# AE402FA0E5597BE0_CM55_HE_View register map
Vendor: Alif Semiconductor; Series: E4; File version: 1.0
CPU: CM55 r1p0, selectable endian, MPU, FPU, double-precision FPU, DSP, VTOR, 8 interrupt priority bits, 1 SAU regions
Registers are 32-bit, read-write, reset 0x0 unless marked. A register's access mark holds for its fields unless they carry their own. Offsets are from the block's base; [hi:lo] are bit positions.

## ETH (part 4 of 4)
Base 0x48100000
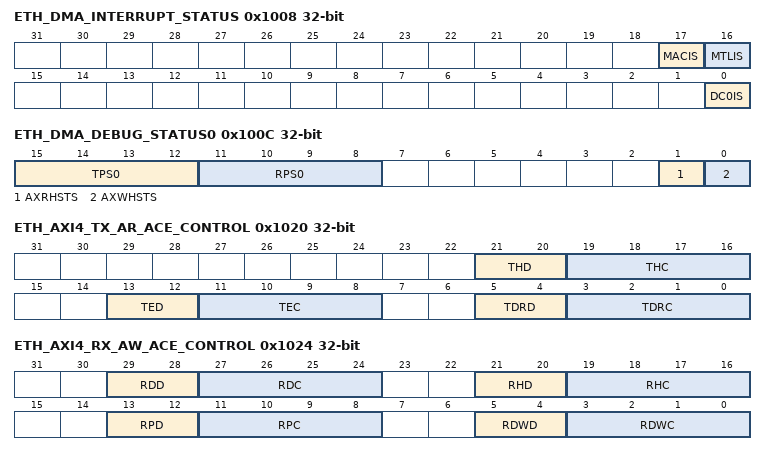
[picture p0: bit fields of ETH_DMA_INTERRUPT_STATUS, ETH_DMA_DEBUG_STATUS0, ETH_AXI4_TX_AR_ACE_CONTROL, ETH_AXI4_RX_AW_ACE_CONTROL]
0x1008 ETH_DMA_INTERRUPT_STATUS ro — DMA, MTL, and MAC Interrupt Status Register
  [17] MACIS — MAC Interrupt Status This bit indicates an interrupt event in the MAC. To reset this bit to 0x0, the software must read the corresponding register in the MAC to get the exact cause of the interrupt and clear its source.
    0=MAC interrupt status not detected; 1=MAC interrupt status detected
  [16] MTLIS — MTL Interrupt Status This bit indicates an interrupt event in the MTL. To reset this bit to 0x0, the software must read the corresponding register in the MTL to get the exact cause of the interrupt and clear its source.
    0=MTL interrupt status not detected; 1=MTL interrupt status detected
  [0] DC0IS — DMA Channel 0 Interrupt Status This bit indicates an interrupt event in DMA Channel 0. To reset this bit to 0x0, the software must read the corresponding register in DMA Channel 0 to get the exact cause of the interrupt and clear its source.
    0=DMA channel 0 interrupt status not detected; 1=DMA channel 0 interrupt status detected
0x100C ETH_DMA_DEBUG_STATUS0 ro — Debug Status 0 Register
  [15:12] TPS0 — DMA Channel 0 Transmit Process State This field indicates the Tx DMA FSM state for Channel 0. The MSB of this field always returns 0. This field does not generate an interrupt.
    0=Stopped (reset or stop transmit command issued); 1=Running (fetching Tx transfer descriptor); 2=Running (waiting for status); 3=Running (reading data from system memory buffer and queuing it to the Tx buffer (Tx FIFO)); 4=Timestamp write state; 6=Suspended (Tx descriptor unavailable or Tx buffer underflow); 7=Running (closing Tx descriptor)
  [11:8] RPS0 — DMA Channel 0 Receive Process State This field indicates the Rx DMA FSM state for Channel 0. The MSB of this field always returns 0. This field does not generate an interrupt.
    0=Stopped (reset or stop receive command issued); 1=Running (fetching Rx transfer descriptor); 3=Running (waiting for Rx packet); 4=Suspended (Rx descriptor unavailable); 5=Running (closing the Rx descriptor); 6=Timestamp write state; 7=Running (transferring the received packet data from the Rx buffer to the system memory)
  [1] AXRHSTS — AXI Master Read Channel Status When high, this bit indicates that the read channel of the AXI master is active, and it is transferring the data.
    0=AXI master read channel status not detected; 1=AXI master read channel status detected
  [0] AXWHSTS — AXI Master Write Channel When high, this bit indicates that the write channel of the AXI master is active, and it is transferring data.
    0=AXI master write channel status not detected; 1=AXI master write channel status detected
0x1020 ETH_AXI4_TX_AR_ACE_CONTROL — AXI4 TX DMA Read ACE Control Register
  [21:20] THD — Transmit DMA First Packet Buffer or TSO Header Domain Control When TSO is NOT enabled, This field is used to drive ardomain_m_o[1:0] signal when Transmit DMA is accessing First Buffer of the Packet (First valid buffer with FD being set in the TDES3 of the Descriptor).When TSO is enabled, This field is used to drive ardomain_m_o[1:0] signal when the Transmit DMA is accessing the TSO Header data.
  [19:16] THC — Transmit DMA First Packet Buffer or TSO Header Cache Control When TSO is NOT enabled, This field is used to drive arcache_m_o[3:0] signal when Transmit DMA is accessing First Buffer of the Packet (First valid buffer with FD being set in the TDES3 of the Descriptor).When TSO is enabled, This field is used to drive arcache_m_o[3:0] signal when the Transmit DMA is accessing the TSO Header data.
  [13:12] TED — Transmit DMA Extended Packet Buffer or TSO Payload Domain Control When TSO is NOT enabled, This field is used to drive ardomain_m_o[1:0] signal when Transmit DMA is accessing the extended buffers (when packet is distributed across multiple buffers).When TSO is enabled, This field is used to drive ardomain_m_o[1:0] signal when the Transmit DMA is accessing the TSO payload data.
  [11:8] TEC — Transmit DMA Extended Packet Buffer or TSO Payload Cache Control When TSO is NOT enabled, This field is used to drive arcache_m_o[3:0] signal when Transmit DMA is accessing the extended buffers (when packet is distributed across multiple buffers).When TSO is enabled, This field is used to drive arcache_m_o[3:0] signal when the Transmit DMA is accessing the TSO payload data.
  [5:4] TDRD — Transmit DMA Read Descriptor Domain Control This field is used to drive ardomain_m_o[1:0] signal when Transmit DMA engines access the Descriptor.
  [3:0] TDRC — Transmit DMA Read Descriptor Cache Control This field is used to drive arcache_m_o[3:0] signal when Transmit DMA engines access the Descriptor.
0x1024 ETH_AXI4_RX_AW_ACE_CONTROL — AXI4 RX DMA Write ACE Control Register
  [29:28] RDD — Receive DMA Buffer Domain Control This field is used to drive the awdomain_m_o[1:0] signal when Receive DMA is accessing the Buffer when Header and payload are NOT separated.
  [27:24] RDC — Receive DMA Buffer Cache Control This field is used to drive awcache_m_o[3:0] signal when Receive DMA is accessing the Buffer when Header and payload are NOT separated.
  [21:20] RHD — Receive DMA Header Domain Control This field is used to drive awdomain_m_o[1:0] and signal when Receive DMA is accessing the header Buffer when Header and payload are separated.
  [19:16] RHC — Receive DMA Header Cache Control This field is used to drive awcache_m_o[3:0] and signal when Receive DMA is accessing the header Buffer when Header and payload are separated.
  [13:12] RPD — Receive DMA Payload Domain Control This field is used to drive awdomain_m_o[1:0] signal when Receive DMA is accessing the Payload Buffer when Header and payload are separated.
  [11:8] RPC — Receive DMA Payload Cache Control This field is used to drive awcache_m_o[3:0] signal when Receive DMA is accessing the Payload Buffer when Header and payload are separated.
  [5:4] RDWD — Receive DMA Write Descriptor Domain Control This field is used to drive awdomain_m_o[1:0] signal when Receive DMA accesses the Descriptor.
  [3:0] RDWC — Receive DMA Write Descriptor Cache Control This field is used to drive awcache_m_o[3:0] signal when Receive DMA accesses the Descriptor.
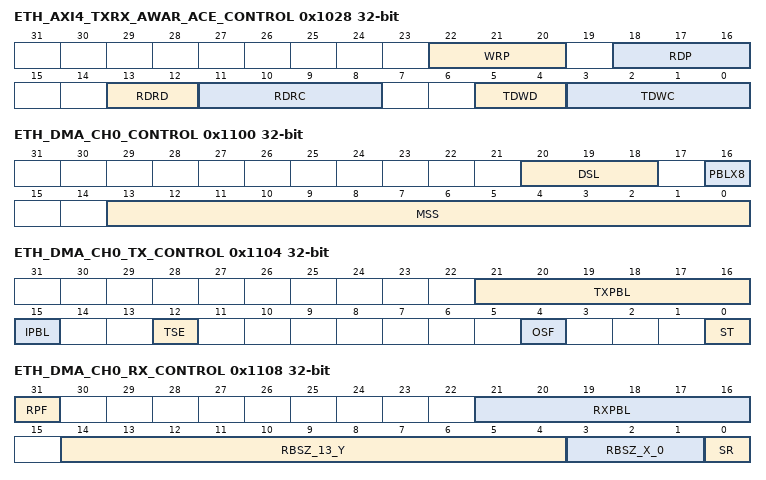
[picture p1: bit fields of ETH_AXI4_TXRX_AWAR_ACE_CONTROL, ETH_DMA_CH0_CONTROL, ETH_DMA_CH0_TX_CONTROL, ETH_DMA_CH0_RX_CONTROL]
0x1028 ETH_AXI4_TXRX_AWAR_ACE_CONTROL — AXI4 TX/RX DMA Read/Write ACE Control Register
  [22:20] WRP — DMA Write Protection control This field is used to drive awprot_m_o[2:0] signal on the AXI Write Channel.
  [18:16] RDP — DMA Read Protection control This field is used to drive arprot_m_o[2:0] signal during all read requests.
  [13:12] RDRD — Receive DMA Read Descriptor Domain control This field is used to drive ardomain_m_o[1:0] signal when Receive DMA engines read the Descriptor.
  [11:8] RDRC — Receive DMA Read Descriptor Cache control This field is used to drive arcache_m_o[3:0] signal when Receive DMA engines read the Descriptor.
  [5:4] TDWD — Transmit DMA Write Descriptor Domain control This field is used to drive awdomain_m_o[1:0] signal when Transmit DMA write to the Descriptor.
  [3:0] TDWC — Transmit DMA Write Descriptor Cache control This field is used to drive awcache_m_o[3:0] signal when Transmit DMA writes to the Descriptor.
0x1040 ETH_AXI_LPI_ENTRY_INTERVAL — AXI LPI Entry Interval Register
  [3:0] LPIEI — LPI Entry Interval Contains the number of system clock cycles, multiplied by 64, to wait for an activity in the ETH module to enter into the AXI low power state. 0x0 indicates 64 clock cycles
0x1100 ETH_DMA_CH0_CONTROL — DMA Channel 0 Control Register
  [20:18] DSL — Descriptor Skip Length This bit specifies the Dword to skip between two unchained descriptors. The address skipping starts from the end of the current descriptor to the start of the next descriptor. When the DSL value is equal to zero, the DMA takes the descriptor table as contiguous.
  [16] PBLX8 — 8xPBL mode When this bit is set, the PBL value programmed in the ETH_DMA_CH0_TX_CONTROL[TXPBL] and ETH_DMA_CH0_RX_CONTROL[RXPBL] fields is multiplied by eight times. Therefore, the DMA transfers the data in 8, 16, 32, 64, 128, and 256 beats depending on the PBL value.
    0=8xPBL mode is disabled; 1=8xPBL mode is enabled
  [13:0] MSS — Maximum Segment Size This field specifies the maximum segment size that must be used while segmenting the packet. This field is valid only if the ETH_DMA_CH0_TX_CONTROL[TSE] bit is set. Program a value in this field that is more than the configured datawidth in bytes. Use MSS value of 64 bytes or more.
0x1104 ETH_DMA_CH0_TX_CONTROL — DMA Channel 0 Transmit Control Register
  [21:16] TXPBL — Transmit Programmable Burst Length These bits indicate the maximum number of beats to be transferred in one DMA block data transfer. The DMA always attempts max burst as specified in PBL each time it starts a burst transfer on the application bus. The user can program PBL with any of the following values: 1, 2, 4, 8, 16, or 32. Any other value results in undefined behavior. To transfer more than 32 beats, perform the following steps: 1. Set the 8xPBL mode in ETH_DMA_CH0_CONTROL register. 2. Set the TxPBL. Note: The maximum value of TxPBL must be less than or equal to half the Tx Queue size in terms of beats. This is required so that the Tx Queue has space to store at least another Tx PBL worth of data while the MTL Tx Queue Controller is transferring data to MAC. For example, the total locations in Tx Queue of size 512 bytes is 64, TxPBL and 8xPBL needs to be programmed to less than or equal to 32.
  [15] IPBL — Ignore PBL Requirement When this bit is set, the DMA does not check for PBL number of locations in the MTL before initiating a transfer. If space is not available, the MTL might use handshaking to slow the DMA. Note: This bit/mode must not be used when multiple Transmit DMA Channels are enabled as it might block other Transmit and Receive DMA Channels from accessing the Read Data Channel of the AXI bus until space is available in Transmit Queue for current transfer.
    0=Ignore PBL requirement is disabled; 1=Ignore PBL requirement is enabled
  [12] TSE — TCP Segmentation Enabled When this bit is set, the DMA performs the TCP segmentation or UDP Segmentation/Fragmentation for packets in this channel. The TCP segmentation or UDP packet's segmentation/Fragmentation is done only for those packets for which the TSE bit (TDES0[19]) is set in the Tx Normal descriptor.When this bit is set, the TxPBL value must be greater than 4.
    0=TCP segmentation is disabled; 1=TCP segmentation is enabled
  [4] OSF — Operate on Second Packet When this bit is set, it instructs the DMA to process the second packet of the Transmit data even before the status for the first packet is obtained.
    0=Operate on second packet disabled; 1=Operate on second packet enabled
  [0] ST — Start or Stop Transmission Command When this bit is set, transmission is placed in the Running state. The DMA checks the Transmit list at the current position for a packet to be transmitted. The DMA tries to acquire descriptor from either of the following positions: The current position in the list The position at which the transmission was previously stopped When this bit is reset, the transmission process is placed in the Stopped state after completing the transmission of the current packet. The Next Descriptor position in the Transmit list is saved, and it becomes the current position when the transmission is restarted. To change the list address, the user needs to program ETH_DMA_CH0_TXDESC_LIST_ADDRESS register with a new value when this bit is reset. The new value is considered when this bit is set again. The stop transmission command is effective only when the transmission of the current packet is complete or the transmission is in the Suspended state.
    0=Stop transmission command; 1=Start transmission command
0x1108 ETH_DMA_CH0_RX_CONTROL — DMA Channel 0 Receive Control Register
  [31] RPF — Rx Packet Flush. When this bit is set to 1, then the ETH module automatically flushes the packet from the Rx Queues destined to this DMA Rx Channel, when it is stopped. When this bit remains set and the DMA is re-started by the software driver, the packets residing in the Rx Queues that were received when this Rx DMA was stopped, still get flushed out. The packets received by the MAC only after the DMA is re-started is routed to the Rx DMA. The flushing is done on the Read side of the Rx Queue. When the packet is duplicated to multiple Rx DMA, it is flushed by the Rx DMA to which it is routed only when it is stopped to prevent head-of-line blocking. The packet duplicated to multiple Rx DMA is not flushed when the Rx DMA is re-started, irrespective of whether the packet was received during one or more Rx DMAs were stopped. When this bit is set to 0, the ETH module does not flush the packet in the Rx Queue destined to this Rx DMA Channel when it is in STOP state. This might in turn cause head-of-line blocking in the corresponding RxQueue. Note: The stopping of packet flow from a Rx DMA Channel to the application by setting RPF works only when there is one-to-one mapping of Rx Queue to Rx DMA channels. In Dynamic mapping mode, setting RPF bit in any ETH_DMA_CH0_RX_CONTROL register might flush packets from unintended Rx Queues which are destined to the stopped Rx DMA Channel.
    0=Rx packet flush is disabled; 1=Rx packet flush is enabled
  [21:16] RXPBL — Receive Programmable Burst Length These bits indicate the maximum number of beats to be transferred in one DMA block data transfer. The DMA always attempts max burst as specified in PBL each time it starts a burst transfer on the application bus. The user can program PBL with any of the following values: 1, 2, 4, 8, 16, or 32. Any other value results in undefined behavior. To transfer more than 32 beats, perform the following steps: 1. Set the 8xPBL mode in the ETH_DMA_CH0_CONTROL register. 2. Set the RxPBL. Note: The maximum value of RxPBL must be less than or equal to half the Rx Queue size in terms of beats. This is required so that the Rx Queue has space to store at least another Rx PBL worth of data while the Rx DMA is transferring a block of data. For example, the total locations in Rx Queue of size 512 bytes is 64, so RxPBL and 8xPBL needs to be programmed to less than or equal to 32.
  [14:4] RBSZ_13_Y — Receive Buffer Size High RBSZ[13-0] is split into two fields higher RBSZ_13_y and lower RBSZ_x_0. The RBSZ[13-0] field indicates the size of the Rx buffers specified in bytes. The maximum buffer size is limited to 16KB. The buffer size is applicable to payload buffers when split headers are enabled. Note: The buffer size must be a multiple of 8. This is required even if the value of buffer address pointer is not aligned to data bus width. Hence the lower RBSZ_x_0 bits are read-only and the value is considered as all-zero. Thus the RBSZ_13_y indicates the buffer size in terms of locations.
  [3:1] RBSZ_X_0 ro — Receive Buffer Size Low RBSZ[13-0] is split into two fields RBSZ_13_Y and RBSZ_X_0. The RBSZ_X_0 is the lower field.
  [0] SR — Start or Stop Receive When this bit is set, the DMA tries to acquire the descriptor from the Receive list and processes the incoming packets. The DMA tries to acquire descriptor from either of the following positions: - The current position in the list. This is the address set by the ETH_DMA_CH0_RXDESC_LIST_ADDRESS register. - The position at which the Rx process was previously stopped. If the DMA does not own the current descriptor, the reception is suspended and the ETH_DMA_CH0_STATUS[RBU] bit is set. The Start Receive command is effective only when the reception is stopped. If the command is issued before setting the ETH_DMA_CH0_RXDESC_LIST_ADDRESS register, the DMA behavior is unpredictable. When this bit is reset, the Rx DMA operation stops after the transfer of the current packet. The next descriptor position in the Receive list is saved, and it becomes the current position after the Rx process is restarted. The Stop Receive command is effective only when the Rx process is in the Running (waiting for Rx packet) or Suspended state.
    0=Stop receive; 1=Start receive
0x1114 ETH_DMA_CH0_TXDESC_LIST_ADDRESS — DMA Channel 0 Transmit Descriptor List Address Register
  [31:3] TDESLA — Start of Transmit List This field contains the base address of the first descriptor in the Transmit descriptor list.
0x111C ETH_DMA_CH0_RXDESC_LIST_ADDRESS — DMA Channel 0 Receive Descriptor List Address Register
  [31:3] RDESLA — Start of Receive List This field contains the base address of the first descriptor in the Rx Descriptor list.
0x1120 ETH_DMA_CH0_TXDESC_TAIL_POINTER — DMA Channel 0 Transmit Descriptor Tail Pointer Register
  [31:3] TDTP — Transmit Descriptor Tail Pointer This field contains the tail pointer for the Tx descriptor ring. The software writes the tail pointer to add more descriptors to the Tx channel. The hardware tries to transmit all packets referenced by the descriptors between the head and the tail pointer registers.
0x1128 ETH_DMA_CH0_RXDESC_TAIL_POINTER — DMA Channel 0 Receive Descriptor Tail Pointer Register
  [31:3] RDTP — Receive Descriptor Tail Pointer This field contains the tail pointer for the Rx descriptor ring. The software writes the tail pointer to add more descriptors to the Rx channel. The hardware tries to write all received packets to the descriptors referenced between the head and the tail pointer registers.
0x112C ETH_DMA_CH0_TXDESC_RING_LENGTH — DMA Channel 0 Transmit Descriptor Ring Length Register
  [9:0] TDRL — Transmit Descriptor Ring Length This field sets the maximum number of Tx descriptors in the circular descriptor ring. The maximum number of descriptors is limited to 1KB descriptors. It is recommended a minimum ring descriptor length of 4. For example, any value up to 0x3FF can be programmed in this field. If 0x3FF is programmed, the descriptors are 1024. If 10 descriptors are needed, program it to a value of 0x9.
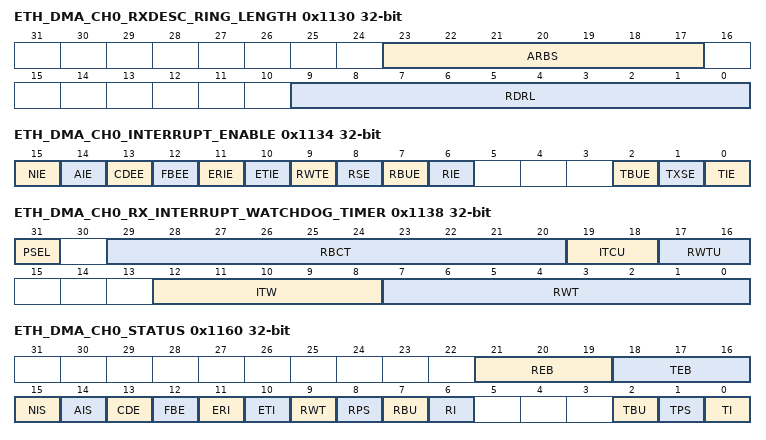
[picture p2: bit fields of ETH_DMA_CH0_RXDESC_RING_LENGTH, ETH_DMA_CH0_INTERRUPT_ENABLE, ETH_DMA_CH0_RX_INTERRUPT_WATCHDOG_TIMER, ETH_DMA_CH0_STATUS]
0x1130 ETH_DMA_CH0_RXDESC_RING_LENGTH — DMA Channel 0 Receive Descriptor Ring Length Register
  [23:17] ARBS — Alternate Receive Buffer Size When ARBS is programmed to a non-zero value and split header feature is not enabled, ARBS indicates the size (in bytes) for Rx Buffer 1. When split header feature is enabled, ARBS indicates the buffer size for header data. The maximum alternate buffer is limited to 1016 bytes. When ARBS = 0, Rx Buffer 1 and Rx Buffer 2 sizes are based on the RBSZ field of the ETH_DMA_CH0_RX_CONTROL register.
  [9:0] RDRL — Receive Descriptor Ring Length This register sets the maximum number of Rx descriptors in the circular descriptor ring. The maximum number of descriptors is limited to 1KB descriptors. For example, any value up to 0x3FF can be programmed in this field. If 0x3FF is programmed, the descriptors are 1024. If 10 descriptors are needed, program it to a value of 0x9.
0x1134 ETH_DMA_CH0_INTERRUPT_ENABLE — DMA Channel 0 Interrupt Enable Register
  [15] NIE — Normal Interrupt Summary Enable When this bit is set, the normal interrupt summary is enabled. This bit enables the following interrupts in the ETH_DMA_CH0_STATUS register: Bit 0: Transmit Interrupt Bit 2: Transmit Buffer Unavailable Bit 6: Receive Interrupt Bit 11: Early Receive Interrupt
    0=Normal interrupt summary is disabled; 1=Normal interrupt summary is enabled
  [14] AIE — Abnormal Interrupt Summary Enable When this bit is set, the abnormal interrupt summary is enabled. This bit enables the following interrupts in the ETH_DMA_CH0_STATUS register: Bit 1: Transmit Process Stopped Bit 7: Rx Buffer Unavailable Bit 8: Receive Process Stopped Bit 9: Receive Watchdog Timeout Bit 10: Early Transmit Interrupt Bit 12: Fatal Bus Error Bit 13: Context Descriptor Error
    0=Abnormal interrupt summary is disabled; 1=Abnormal interrupt summary is enabled
  [13] CDEE — Context Descriptor Error Enable When this bit is set along with the AIE bit, the descriptor error interrupt is enabled. When this bit is reset, the descriptor error interrupt is disabled.
    0=Context descriptor error is disabled; 1=Context descriptor error is enabled
  [12] FBEE — Fatal Bus Error Enable When this bit is set along with the AIE bit, the fatal bus error interrupt is enabled. When this bit is reset, the fatal bus error error interrupt is disabled.
    0=Fatal bus error is disabled; 1=Fatal bus error is enabled
  [11] ERIE — Early Receive Interrupt Enable When this bit is set along with the NIE bit, the early receive interrupt is enabled. When this bit is reset, the early receive interrupt is disabled.
    0=Early receive interrupt is disabled; 1=Early receive interrupt is enabled
  [10] ETIE — Early Transmit Interrupt Enable When this bit is set along with the AIE bit, the early transmit interrupt is enabled. When this bit is reset, the early transmit interrupt is disabled.
    0=Early transmit interrupt is disabled; 1=Early transmit interrupt is enabled
  [9] RWTE — Receive Watchdog Timeout Enable When this bit is set along with the AIE bit, the receive watchdog timeout interrupt is enabled. When this bit is reset, the receive watchdog timeout interrupt is disabled.
    0=Receive watchdog timeout is disabled; 1=Receive watchdog timeout is enabled
  [8] RSE — Receive Stopped Enable When this bit is set along with the AIE bit, the receive stopped interrupt is enabled. When this bit is reset, the receive stopped interrupt is disabled.
    0=Receive stopped is disabled; 1=Receive stopped is enabled
  [7] RBUE — Receive Buffer Unavailable Enable When this bit is set along with the AIE bit, the receive buffer unavailable interrupt is enabled. When this bit is reset, the receive buffer unavailable interrupt is disabled.
    0=Receive buffer unavailable is disabled; 1=Receive buffer unavailable is enabled
  [6] RIE — Receive Interrupt Enable When this bit is set along with the NIE bit, the receive interrupt is enabled. When this bit is reset, the receive interrupt is disabled.
    0=Receive interrupt is disabled; 1=Receive interrupt is enabled
  [2] TBUE — Transmit Buffer Unavailable Enable When this bit is set along with the NIE bit, the transmit buffer unavailable interrupt is enabled. When this bit is reset, the transmit buffer unavailable interrupt is disabled.
    0=Transmit buffer unavailable is disabled; 1=Transmit buffer unavailable is enabled
  [1] TXSE — Transmit Stopped Enable When this bit is set along with the AIE bit, the transmission stopped interrupt is enabled. When this bit is reset, the transmission stopped interrupt is disabled.
    0=Transmit stopped is disabled; 1=Transmit stopped is enabled
  [0] TIE — Transmit Interrupt Enable When this bit is set along with the NIE bit, the transmit interrupt is enabled. When this bit is reset, the transmit interrupt is disabled.
    0=Transmit interrupt is disabled; 1=Transmit interrupt is enabled
0x1138 ETH_DMA_CH0_RX_INTERRUPT_WATCHDOG_TIMER — DMA Channel 0 Receive Interrupt Watchdog Timer Register
  [31] PSEL — Packet Count Interrupt Select When this bit is set, RBCT field indicates the number of packet threshold at which the Receive Interrupt (RI) is activated and the watchdog timer reset. When this bit is low, RBCT field indicates the number of data byte threshold at which the Receive Interrupt (RI) is activated and the watchdog timer reset.
    0=RBCT field is used to generate interrupt based on number of bytes received; 1=RBCT field is used to generate interrupt based on number of packets received
  [29:20] RBCT — Receive Byte Count Threshold This field sets the limit in number of bytes or number of RX packets (based on PSEL) transferred without the assertion of Receive Interrupt. Once this limit is crossed, Receive interrupt is asserted, and the watchdog timer (corresponding to RWT) is also reset. This function is valid only when set to a non-zero value. When RBCT = 0, RX Packet/Byte counter is inactive. When PSEL = 0, this field is multiplied by 1024, to get the actual number of byte threshold. When PSEL =1, RBCT value is directly used. Thus the maximum limit is 511 packets or 511 x 1024 bytes, respectively.
  [19:18] ITCU — Receive Idle Timer Count Units This fields indicates the number of system clock cycles corresponding to one unit in ITW field.
    0=256; 1=512; 2=1024; 3=2048
  [17:16] RWTU — Receive Interrupt Watchdog Timer Count Units This fields indicates the number of system clock cycles corresponding to one unit in RWT field.
    0=256; 1=512; 2=1024; 3=2048
  [12:8] ITW — Receive Idle Timer Window This field when programmed with a non-zero value, enables operation of the Rx Idle Timer. The timer window is determined in number of system clock cycles when this field is multiplied by the ITCU unit.
  [7:0] RWT — Receive Interrupt Watchdog Timer Count This field indicates the number of system clock cycles, multiplied by factor indicated in RWTU field, for which the watchdog timer is set. The watchdog timer is triggered with the programmed value after the Rx DMA completes the transfer of a packet for which the RI bit is not set in the ETH_DMA_CH0_STATUS register, because of the setting of Interrupt Enable bit in the corresponding descriptor RDES3[30]. When the watchdog timer runs out, the RI bit is set and the timer is stopped. The watchdog timer is reset when the RI bit is set high because of automatic setting of RI as per the Interrupt Enable bit RDES3[30] of any received packet.
0x1144 ETH_DMA_CH0_CURRENT_APP_TXDESC ro — DMA Channel 0 Current Application Transmit Descriptor Register
  [31:0] CURTDESAPTR — Application Transmit Descriptor Address Pointer The DMA updates this pointer during Tx operation. This pointer is cleared on reset.
0x114C ETH_DMA_CH0_CURRENT_APP_RXDESC ro — DMA Channel 0 Current Application Receive Descriptor Register
  [31:0] CURRDESAPTR — Application Receive Descriptor Address Pointer The DMA updates this pointer during Rx operation. This pointer is cleared on reset.
0x1154 ETH_DMA_CH0_CURRENT_APP_TXBUFFER ro — DMA Channel 0 Current Application Transmit Buffer Address Register
  [31:0] CURTBUFAPTR — Application Transmit Buffer Address Pointer The DMA updates this pointer during Tx operation. This pointer is cleared on reset.
0x115C ETH_DMA_CH0_CURRENT_APP_RXBUFFER ro — DMA Channel 0 Current Application Receive Buffer Address Register
  [31:0] CURRBUFAPTR — Application Receive Buffer Address Pointer The DMA updates this pointer during Rx operation. This pointer is cleared on reset.
0x1160 ETH_DMA_CH0_STATUS — DMA Channel 0 Status Register
  [21:19] REB ro — Rx DMA Error Bits This field indicates the type of error that caused a Bus Error. For example, error response on the AXI interface. Bit 21 0x0: No error during data transfer by Rx DMA 0x1: Error during data transfer by Rx DMA Bit 20 0x0: Error during data buffer access 0x1: Error during descriptor access Bit 19 0x0: Error during write transfer 0x1: Error during read transfer
  [18:16] TEB ro — Tx DMA Error Bits This field indicates the type of error that caused a Bus Error. For example, error response on the AXI interface. Bit 18 0x0: No error during data transfer by Tx DMA 0x1: Error during data transfer by Tx DMA Bit 17 0x0: Error during data buffer access 0x1: Error during descriptor access Bit 16 0x0: Error during write transfer 0x1: Error during read transfer
  [15] NIS — Normal Interrupt Summary Normal Interrupt Summary bit value is the logical OR of the following bits when the corresponding interrupt bits are enabled in the ETH_DMA_CH0_INTERRUPT_ENABLE register: Bit 0: Transmit Interrupt Bit 2: Transmit Buffer Unavailable Bit 6: Receive Interrupt Bit 11: Early Receive Interrupt This is a sticky bit. The user must clear this bit (by writing 1 to this bit) each time a corresponding bit which causes NIS to be set is cleared. Access restriction applies. Self-set to 1 on internal event. Setting 1 clears. Setting 0 has no effect.
    0=Normal interrupt summary status not detected; 1=Normal interrupt summary status detected
  [14] AIS — Abnormal Interrupt Summary Abnormal Interrupt Summary bit value is the logical OR of the following when the corresponding interrupt bits are enabled in the ETH_DMA_CH0_INTERRUPT_ENABLE register: Bit 1: Transmit Process Stopped Bit 7: Receive Buffer Unavailable Bit 8: Receive Process Stopped Bit 10: Early Transmit Interrupt Bit 12: Fatal Bus Error Bit 13: Context Descriptor Error This is a sticky bit. The user must clear this bit (by writing 1 to this bit) each time a corresponding bit, which causes AIS to be set, is cleared. Access restriction applies. Self-set to 1 on internal event. Setting 1 clears. Setting 0 has no effect.
    0=Abnormal interrupt summary status not detected; 1=Abnormal interrupt summary status detected
  [13] CDE — Context Descriptor Error This bit indicates that the DMA Tx/Rx engine received a descriptor error, which indicates invalid context in the middle of packet flow ( intermediate descriptor) or all one's descriptor in Tx case and on Rx side it indicates DMA has read a descriptor with either of the buffer address as ones which is considered to be invalid. Access restriction applies. Self-set to 1 on internal event. Setting 1 clears. Setting 0 has no effect.
    0=Context descriptor error status not detected; 1=Context descriptor error status detected
  [12] FBE — Fatal Bus Error This bit indicates that a bus error occurred (as described in the EB field). When this bit is set, the corresponding DMA channel engine disables all bus accesses. Access restriction applies. Self-set to 1 on internal event. Setting 1 clears. Setting 0 has no effect.
    0=Fatal bus error status not detected; 1=Fatal bus error status detected
  [11] ERI — Early Receive Interrupt This bit when set indicates that the Rx DMA has completed the transfer of packet data to the memory. The setting of RI bit automatically clears this bit. Access restriction applies. Self-set to 1 on internal event. Setting 1 clears. Setting 0 has no effect.
    0=Early receive interrupt status not detected; 1=Early receive interrupt status detected
  [10] ETI — Early Transmit Interrupt This bit when set indicates that the Tx DMA has completed the transfer of packet data to the MTL TXFIFO memory. Access restriction applies. Self-set to 1 on internal event. Setting 1 clears. Setting 0 has no effect.
    0=Early transmit interrupt status not detected; 1=Early transmit interrupt status detected
  [9] RWT — Receive Watchdog Timeout This bit is asserted when a packet with length greater than 2,048 bytes (10,240 bytes when Jumbo Packet mode is enabled) is received.
    0=Receive watchdog timeout status not detected; 1=Receive watchdog timeout status detected
  [8] RPS — Receive Process Stopped This bit is asserted when the Rx process enters the Stopped state. Access restriction applies. Self-set to 1 on internal event. Setting 1 clears. Setting 0 has no effect.
    0=Receive process stopped status not detected; 1=Receive process stopped status detected
  [7] RBU — Receive Buffer Unavailable This bit indicates that the application owns the next descriptor in the Receive list, and the DMA cannot acquire it. The Rx process is suspended. To resume processing Rx descriptors, the application should change the ownership of the descriptor and issue a Receive Poll Demand command. If this command is not issued, the Rx process resumes when the next recognized incoming packet is received. In ring mode, the application must advance the Receive Descriptor Tail Pointer register of a channel. This bit is set only when the DMA owns the previous Rx descriptor. Access restriction applies. Self-set to 1 on internal event. Setting 1 clears. Setting 0 has no effect.
    0=Receive buffer unavailable status not detected; 1=Receive buffer unavailable status detected
  [6] RI — Receive Interrupt This bit indicates that the packet reception is complete. When packet reception is complete, Bit 31 of RDES3 is reset in the last descriptor, and the specific packet status information is updated in the descriptor. The reception remains in the Running state. Access restriction applies. Self-set to 1 on internal event. Setting 1 clears. Setting 0 has no effect.
    0=Receive interrupt status not detected; 1=Receive interrupt status detected
  [2] TBU — Transmit Buffer Unavailable This bit indicates that the application owns the next descriptor in the Transmit list, and the DMA cannot acquire it. Transmission is suspended. the ETH_DMA_DEBUG_STATUS0[TPS0] field explains the Transmit Process state transitions. To resume processing the Transmit descriptors, the application must do the following: 1. Change the ownership of the descriptor by setting Bit 31 of TDES3. 2. Issue a Transmit Poll Demand command. For ring mode, the application should advance the Transmit Descriptor Tail Pointer register of a channel. Access restriction applies. Self-set to 1 on internal event. Setting 1 clears. Setting 0 has no effect.
    0=Transmit buffer unavailable status not detected; 1=Transmit buffer unavailable status detected
  [1] TPS — Transmit Process Stopped This bit is set when the transmission is stopped. Access restriction applies. Self-set to 1 on internal event. Setting 1 clears. Setting 0 has no effect.
    0=Transmit process stopped status not detected; 1=Transmit process stopped status detected
  [0] TI — Transmit Interrupt This bit indicates that the packet transmission is complete. When transmission is complete, Bit 31 of TDES3 is reset in the last descriptor, and the specific packet status information is updated in the descriptor. Access restriction applies. Self-set to 1 on internal event. Setting 1 clears. Setting 0 has no effect.
    0=Transmit interrupt status not detected; 1=Transmit interrupt status detected
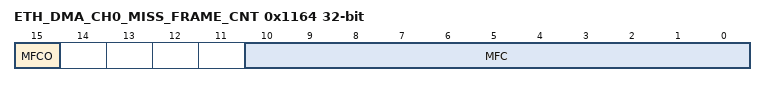
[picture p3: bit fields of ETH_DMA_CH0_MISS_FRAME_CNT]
0x1164 ETH_DMA_CH0_MISS_FRAME_CNT ro — DMA Channel 0 Dropped Packet Counter Register
  [15] MFCO — Overflow status of the MFC Counter When this bit is set then the MFC counter does not get incrementedfurther. The bit gets cleared when this register is read. Access restriction applies. Clears on read. Self-set to 1 on internal event.
    0=Miss frame counter overflow not occurred; 1=Miss frame counter overflow occurred
  [10:0] MFC — Dropped Packet Counters This counter indicates the number of packet counters that are dropped by the DMA either because of bus error or because of programing the ETH_DMA_CH0_CONTROL[RPF] field. The counter gets cleared when this register is read. Access restriction applies. Clears on read. Self-set to 1 on internal event.
